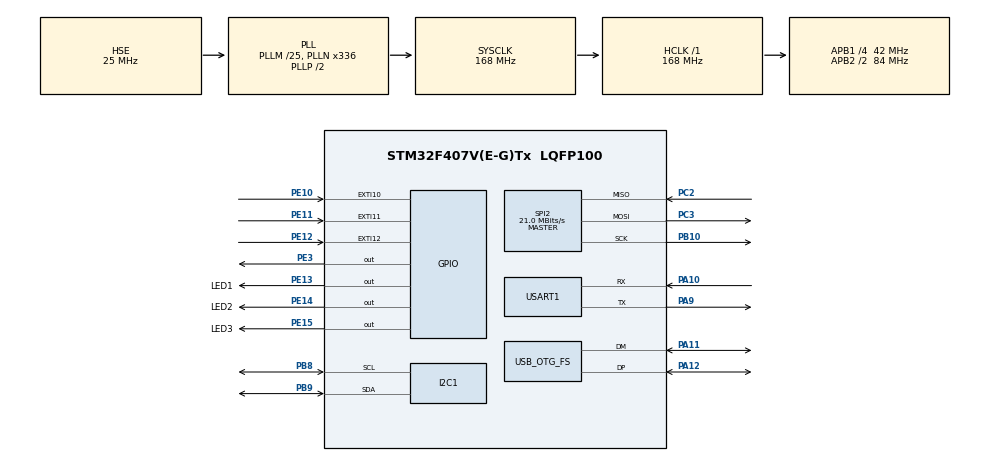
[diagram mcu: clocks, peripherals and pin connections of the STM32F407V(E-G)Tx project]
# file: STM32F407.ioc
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FREERTOS.Tasks01=defaultTask,24,128,StartDefaultTask,Default,NULL,Dynamic,NULL,NULL;myTaskModbus,24,128,StartTaskModbus,Default,NULL,Dynamic,NULL,NULL
I2C1.I2C_Mode=I2C_Fast
Mcu.Family=STM32F4
Mcu.Name=STM32F407V(E-G)Tx
Mcu.Package=LQFP100
NVIC.OTG_FS_IRQn=true\:5\:0\:false\:false\:true\:true\:false\:true
NVIC.PriorityGroup=NVIC_PRIORITYGROUP_4
PA10.Mode=Asynchronous
PA10.Signal=USART1_RX
PA11.Mode=Device_Only
PA11.Signal=USB_OTG_FS_DM
PA12.Mode=Device_Only
PA12.Signal=USB_OTG_FS_DP
PA13.Mode=Serial_Wire
PA13.Signal=SYS_JTMS-SWDIO
PA14.Mode=Serial_Wire
PA14.Signal=SYS_JTCK-SWCLK
PA9.Mode=Asynchronous
PA9.Signal=USART1_TX
PB10.Mode=Full_Duplex_Master
PB10.Signal=SPI2_SCK
PB8.Mode=I2C
PB8.Signal=I2C1_SCL
PB9.Mode=I2C
PB9.Signal=I2C1_SDA
PC2.Mode=Full_Duplex_Master
PC2.Signal=SPI2_MISO
PC3.Mode=Full_Duplex_Master
PC3.Signal=SPI2_MOSI
PE10.Signal=GPXTI10
PE11.Signal=GPXTI11
PE12.Signal=GPXTI12
PE13.GPIO_Label=LED1
PE13.Signal=GPIO_Output
PE14.GPIO_Label=LED2
PE14.Signal=GPIO_Output
PE15.GPIO_Label=LED3
PE15.Signal=GPIO_Output
PE3.Signal=GPIO_Output
PH0-OSC_IN.Mode=HSE-External-Oscillator
PH0-OSC_IN.Signal=RCC_OSC_IN
PH1-OSC_OUT.Mode=HSE-External-Oscillator
PH1-OSC_OUT.Signal=RCC_OSC_OUT
ProjectManager.HeapSize=0x200
ProjectManager.StackSize=0x400
ProjectManager.TargetToolchain=MDK-ARM V5.32
RCC.48MHZClocksFreq_Value=48000000
RCC.AHBFreq_Value=168000000
RCC.APB1CLKDivider=RCC_HCLK_DIV4
RCC.APB1Freq_Value=42000000
RCC.APB1TimFreq_Value=84000000
RCC.APB2CLKDivider=RCC_HCLK_DIV2
RCC.APB2Freq_Value=84000000
RCC.APB2TimFreq_Value=168000000
RCC.CortexFreq_Value=168000000
RCC.HCLKFreq_Value=168000000
RCC.HSE_VALUE=25000000
RCC.HSI_VALUE=16000000
RCC.LSE_VALUE=32768
RCC.PLLM=25
RCC.PLLN=336
RCC.PLLQ=7
RCC.SYSCLKFreq_VALUE=168000000
RCC.SYSCLKSource=RCC_SYSCLKSOURCE_PLLCLK
RCC.VCOOutputFreq_Value=336000000
SPI2.CalculateBaudRate=21.0 MBits/s
SPI2.Direction=SPI_DIRECTION_2LINES
SPI2.Mode=SPI_MODE_MASTER
SPI2.VirtualType=VM_MASTER
USART1.VirtualMode=VM_ASYNC
USB_DEVICE.CLASS_NAME_FS=CDC
USB_DEVICE.VirtualMode-CDC_FS=Cdc
USB_DEVICE.VirtualModeFS=Cdc_FS
USB_OTG_FS.VirtualMode=Device_Only
VP_FREERTOS_VS_CMSIS_V2.Mode=CMSIS_V2
VP_USB_DEVICE_VS_USB_DEVICE_CDC_FS.Mode=CDC_FS
board=custom

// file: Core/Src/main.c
/* USER CODE BEGIN Header */
/**
  ******************************************************************************
  * @file           : main.c
  * @brief          : Main program body
  ******************************************************************************
  * @attention
  *
  * <h2><center>&copy; Copyright (c) 2021 STMicroelectronics.
  * All rights reserved.</center></h2>
  *
  * This software component is licensed by ST under BSD 3-Clause license,
  * the "License"; You may not use this file except in compliance with the
  * License. You may obtain a copy of the License at:
  *                        opensource.org/licenses/BSD-3-Clause
  *
  ******************************************************************************
  */
/* USER CODE END Header */
#include "main.h"
#include "cmsis_os.h"
#include "usb_device.h"
#include "usb_device.h"

I2C_HandleTypeDef hi2c1;

SPI_HandleTypeDef hspi2;

UART_HandleTypeDef huart1;

/* Definitions for defaultTask */
osThreadId_t defaultTaskHandle;
const osThreadAttr_t defaultTask_attributes = {
  .name = "defaultTask",
  .stack_size = 128 * 4,
  .priority = (osPriority_t) osPriorityNormal,
};
/* Definitions for myTaskModbus */
osThreadId_t myTaskModbusHandle;
const osThreadAttr_t myTaskModbus_attributes = {
  .name = "myTaskModbus",
  .stack_size = 128 * 4,
  .priority = (osPriority_t) osPriorityNormal,
};

void SystemClock_Config(void);
static void MX_GPIO_Init(void);
static void MX_I2C1_Init(void);
static void MX_SPI2_Init(void);
static void MX_USART1_UART_Init(void);
void StartDefaultTask(void *argument);
void StartTaskModbus(void *argument);

int main(void)
{

  /* MCU Configuration--------------------------------------------------------*/

  /* Reset of all peripherals, Initializes the Flash interface and the Systick. */
  HAL_Init();

  /* Configure the system clock */
  SystemClock_Config();

  /* Initialize all configured peripherals */
  MX_GPIO_Init();
  MX_I2C1_Init();
  MX_SPI2_Init();
  MX_USART1_UART_Init();

  /* Init scheduler */
  osKernelInitialize();

  /* Create the thread(s) */
  /* creation of defaultTask */
  defaultTaskHandle = osThreadNew(StartDefaultTask, NULL, &defaultTask_attributes);

  /* creation of myTaskModbus */
  myTaskModbusHandle = osThreadNew(StartTaskModbus, NULL, &myTaskModbus_attributes);

  /* Start scheduler */
  osKernelStart();

  /* We should never get here as control is now taken by the scheduler */
  /* Infinite loop */
  while (1)
  {

    /* USER CODE BEGIN 3 */
    HAL_Delay(500);
    HAL_GPIO_TogglePin(LED1_GPIO_Port, LED1_Pin);
  }
  /* USER CODE END 3 */
}

void SystemClock_Config(void)
{
  RCC_OscInitTypeDef RCC_OscInitStruct = {0};
  RCC_ClkInitTypeDef RCC_ClkInitStruct = {0};

  /** Configure the main internal regulator output voltage
  */
  __HAL_RCC_PWR_CLK_ENABLE();
  __HAL_PWR_VOLTAGESCALING_CONFIG(PWR_REGULATOR_VOLTAGE_SCALE1);
  /** Initializes the RCC Oscillators according to the specified parameters
  * in the RCC_OscInitTypeDef structure.
  */
  RCC_OscInitStruct.OscillatorType = RCC_OSCILLATORTYPE_HSE;
  RCC_OscInitStruct.HSEState = RCC_HSE_ON;
  RCC_OscInitStruct.PLL.PLLState = RCC_PLL_ON;
  RCC_OscInitStruct.PLL.PLLSource = RCC_PLLSOURCE_HSE;
  RCC_OscInitStruct.PLL.PLLM = 25;
  RCC_OscInitStruct.PLL.PLLN = 336;
  RCC_OscInitStruct.PLL.PLLP = RCC_PLLP_DIV2;
  RCC_OscInitStruct.PLL.PLLQ = 7;
  if (HAL_RCC_OscConfig(&RCC_OscInitStruct) != HAL_OK)
  {
    Error_Handler();
  }
  /** Initializes the CPU, AHB and APB buses clocks
  */
  RCC_ClkInitStruct.ClockType = RCC_CLOCKTYPE_HCLK|RCC_CLOCKTYPE_SYSCLK
                              |RCC_CLOCKTYPE_PCLK1|RCC_CLOCKTYPE_PCLK2;
  RCC_ClkInitStruct.SYSCLKSource = RCC_SYSCLKSOURCE_PLLCLK;
  RCC_ClkInitStruct.AHBCLKDivider = RCC_SYSCLK_DIV1;
  RCC_ClkInitStruct.APB1CLKDivider = RCC_HCLK_DIV4;
  RCC_ClkInitStruct.APB2CLKDivider = RCC_HCLK_DIV2;

  if (HAL_RCC_ClockConfig(&RCC_ClkInitStruct, FLASH_LATENCY_5) != HAL_OK)
  {
    Error_Handler();
  }
}

static void MX_I2C1_Init(void)
{

  hi2c1.Instance = I2C1;
  hi2c1.Init.ClockSpeed = 400000;
  hi2c1.Init.DutyCycle = I2C_DUTYCYCLE_2;
  hi2c1.Init.OwnAddress1 = 0;
  hi2c1.Init.AddressingMode = I2C_ADDRESSINGMODE_7BIT;
  hi2c1.Init.DualAddressMode = I2C_DUALADDRESS_DISABLE;
  hi2c1.Init.OwnAddress2 = 0;
  hi2c1.Init.GeneralCallMode = I2C_GENERALCALL_DISABLE;
  hi2c1.Init.NoStretchMode = I2C_NOSTRETCH_DISABLE;
  if (HAL_I2C_Init(&hi2c1) != HAL_OK)
  {
    Error_Handler();
  }

}

static void MX_SPI2_Init(void)
{

  /* SPI2 parameter configuration*/
  hspi2.Instance = SPI2;
  hspi2.Init.Mode = SPI_MODE_MASTER;
  hspi2.Init.Direction = SPI_DIRECTION_2LINES;
  hspi2.Init.DataSize = SPI_DATASIZE_8BIT;
  hspi2.Init.CLKPolarity = SPI_POLARITY_LOW;
  hspi2.Init.CLKPhase = SPI_PHASE_1EDGE;
  hspi2.Init.NSS = SPI_NSS_SOFT;
  hspi2.Init.BaudRatePrescaler = SPI_BAUDRATEPRESCALER_2;
  hspi2.Init.FirstBit = SPI_FIRSTBIT_MSB;
  hspi2.Init.TIMode = SPI_TIMODE_DISABLE;
  hspi2.Init.CRCCalculation = SPI_CRCCALCULATION_DISABLE;
  hspi2.Init.CRCPolynomial = 10;
  if (HAL_SPI_Init(&hspi2) != HAL_OK)
  {
    Error_Handler();
  }

}

static void MX_USART1_UART_Init(void)
{

  huart1.Instance = USART1;
  huart1.Init.BaudRate = 115200;
  huart1.Init.WordLength = UART_WORDLENGTH_8B;
  huart1.Init.StopBits = UART_STOPBITS_1;
  huart1.Init.Parity = UART_PARITY_NONE;
  huart1.Init.Mode = UART_MODE_TX_RX;
  huart1.Init.HwFlowCtl = UART_HWCONTROL_NONE;
  huart1.Init.OverSampling = UART_OVERSAMPLING_16;
  if (HAL_UART_Init(&huart1) != HAL_OK)
  {
    Error_Handler();
  }

}

static void MX_GPIO_Init(void)
{
  GPIO_InitTypeDef GPIO_InitStruct = {0};

  /* GPIO Ports Clock Enable */
  __HAL_RCC_GPIOE_CLK_ENABLE();
  __HAL_RCC_GPIOH_CLK_ENABLE();
  __HAL_RCC_GPIOC_CLK_ENABLE();
  __HAL_RCC_GPIOB_CLK_ENABLE();
  __HAL_RCC_GPIOA_CLK_ENABLE();

  /*Configure GPIO pin Output Level */
  HAL_GPIO_WritePin(GPIOE, GPIO_PIN_3|LED1_Pin|LED2_Pin|LED3_Pin, GPIO_PIN_RESET);

  /*Configure GPIO pins : PE3 LED1_Pin LED2_Pin LED3_Pin */
  GPIO_InitStruct.Pin = GPIO_PIN_3|LED1_Pin|LED2_Pin|LED3_Pin;
  GPIO_InitStruct.Mode = GPIO_MODE_OUTPUT_PP;
  GPIO_InitStruct.Pull = GPIO_NOPULL;
  GPIO_InitStruct.Speed = GPIO_SPEED_FREQ_LOW;
  HAL_GPIO_Init(GPIOE, &GPIO_InitStruct);

  /*Configure GPIO pins : PE10 PE11 PE12 */
  GPIO_InitStruct.Pin = GPIO_PIN_10|GPIO_PIN_11|GPIO_PIN_12;
  GPIO_InitStruct.Mode = GPIO_MODE_IT_RISING;
  GPIO_InitStruct.Pull = GPIO_NOPULL;
  HAL_GPIO_Init(GPIOE, &GPIO_InitStruct);

}

void StartDefaultTask(void *argument)
{
  /* init code for USB_DEVICE */
  MX_USB_DEVICE_Init();
  for(;;)
  {
    osDelay(1);
  }
}

void StartTaskModbus(void *argument)
{
  for(;;)
  {
    osDelay(1);
  }
}

void Error_Handler(void)
{
  __disable_irq();
  while (1)
  {
  }
}

/************************ (C) COPYRIGHT STMicroelectronics *****END OF FILE****/
